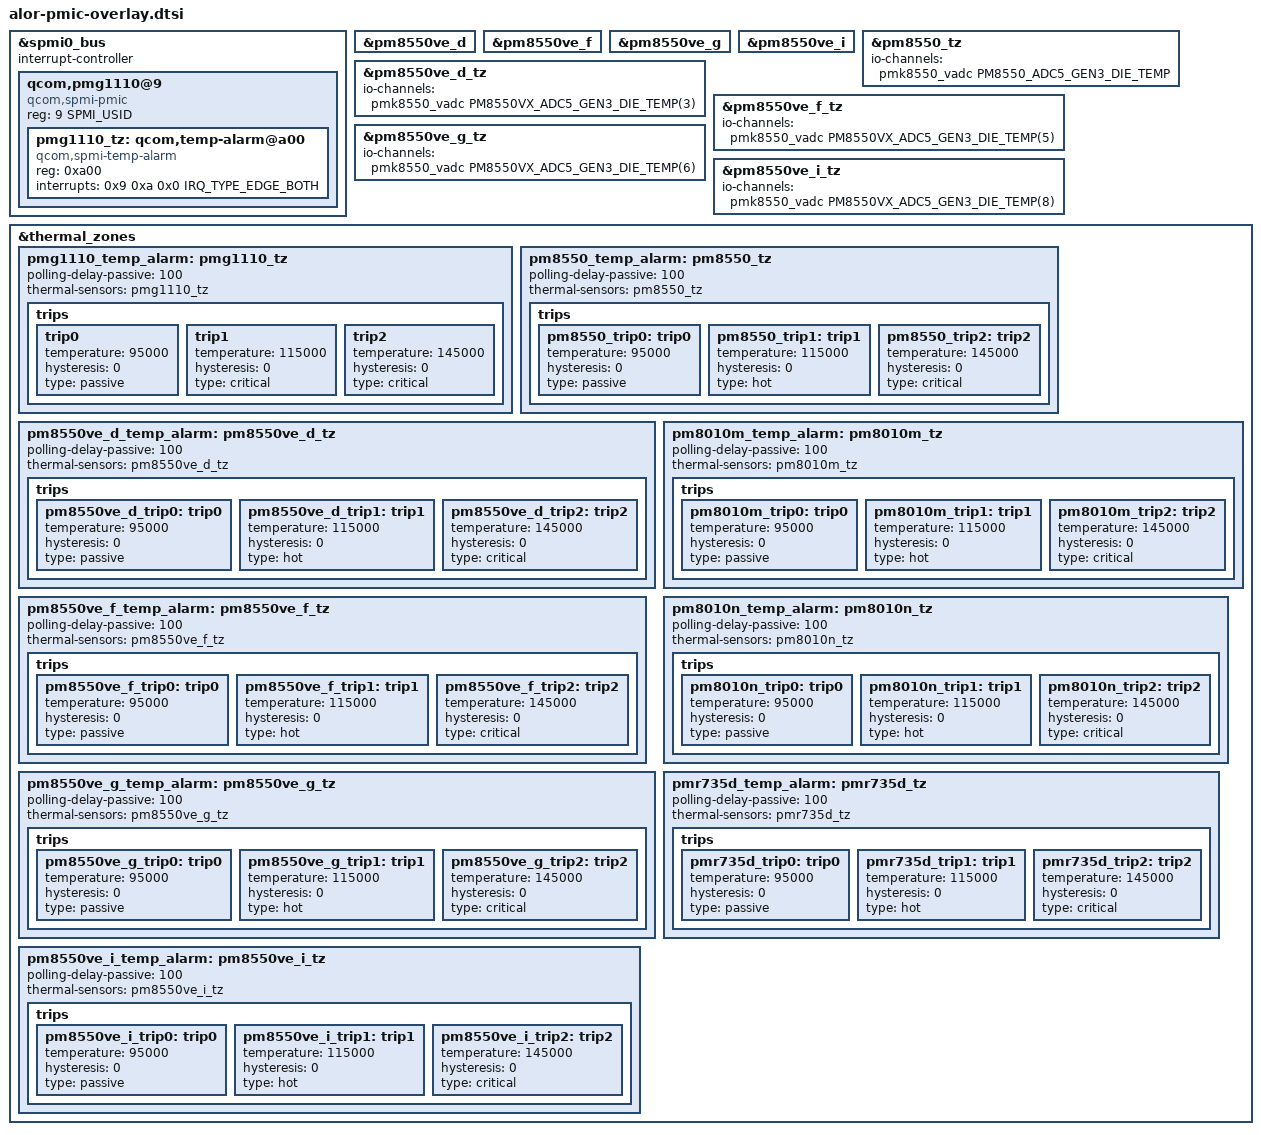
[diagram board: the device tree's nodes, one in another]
// SPDX-License-Identifier: BSD-3-Clause
/*
 * Copyright (c) 2025 Qualcomm Innovation Center, Inc. All rights reserved.
 */

#include <dt-bindings/gpio/gpio.h>

&spmi0_bus {
	#include "pmk8550.dtsi"
	#include "pm8550.dtsi"
	#include "pm8550ve.dtsi"
	#include "pmr735d.dtsi"
	#include "pm8010.dtsi"
};

&pm8550ve_d {
	status = "ok";
};

&pm8550ve_f {
	status = "ok";
};

&pm8550ve_g {
	status = "ok";
};

&pm8550ve_i {
	status = "ok";
};

&pm8550_tz {
	io-channels = <&pmk8550_vadc PM8550_ADC5_GEN3_DIE_TEMP>;
	io-channel-names = "thermal";
};

&pm8550ve_d_tz {
	io-channels = <&pmk8550_vadc PM8550VX_ADC5_GEN3_DIE_TEMP(3)>;
	io-channel-names = "thermal";
};

&pm8550ve_f_tz {
	io-channels = <&pmk8550_vadc PM8550VX_ADC5_GEN3_DIE_TEMP(5)>;
	io-channel-names = "thermal";
};

&pm8550ve_g_tz {
	io-channels = <&pmk8550_vadc PM8550VX_ADC5_GEN3_DIE_TEMP(6)>;
	io-channel-names = "thermal";
};

&pm8550ve_i_tz {
	io-channels = <&pmk8550_vadc PM8550VX_ADC5_GEN3_DIE_TEMP(8)>;
	io-channel-names = "thermal";
};

&spmi0_bus {
	#address-cells = <2>;
	#size-cells = <0>;
	interrupt-controller;
	#interrupt-cells = <4>;

	qcom,pmg1110@9 {
		compatible = "qcom,spmi-pmic";
		reg = <9 SPMI_USID>;
		#address-cells = <1>;
		#size-cells = <0>;

		pmg1110_tz: qcom,temp-alarm@a00 {
			compatible = "qcom,spmi-temp-alarm";
			reg = <0xa00>;
			interrupts = <0x9 0xa 0x0 IRQ_TYPE_EDGE_BOTH>;
			#thermal-sensor-cells = <0>;
		};
	};
};

&thermal_zones {
	pmg1110_temp_alarm: pmg1110_tz {
		polling-delay-passive = <100>;
		thermal-sensors = <&pmg1110_tz>;

		trips {
			trip0 {
				temperature = <95000>;
				hysteresis = <0>;
				type = "passive";
			};

			trip1 {
				temperature = <115000>;
				hysteresis = <0>;
				type = "critical";
			};

			trip2 {
				temperature = <145000>;
				hysteresis = <0>;
				type = "critical";
			};
		};
	};

	pm8550_temp_alarm: pm8550_tz {
		polling-delay-passive = <100>;
		thermal-sensors = <&pm8550_tz>;

		trips {
			pm8550_trip0: trip0 {
				temperature = <95000>;
				hysteresis = <0>;
				type = "passive";
			};

			pm8550_trip1: trip1 {
				temperature = <115000>;
				hysteresis = <0>;
				type = "hot";
			};

			pm8550_trip2: trip2 {
				temperature = <145000>;
				hysteresis = <0>;
				type = "critical";
			};
		};
	};

	pm8550ve_d_temp_alarm: pm8550ve_d_tz {
		polling-delay-passive = <100>;
		thermal-sensors = <&pm8550ve_d_tz>;

		trips {
			pm8550ve_d_trip0: trip0 {
				temperature = <95000>;
				hysteresis = <0>;
				type = "passive";
			};

			pm8550ve_d_trip1: trip1 {
				temperature = <115000>;
				hysteresis = <0>;
				type = "hot";
			};

			pm8550ve_d_trip2: trip2 {
				temperature = <145000>;
				hysteresis = <0>;
				type = "critical";
			};
		};
	};

	pm8550ve_f_temp_alarm: pm8550ve_f_tz {
		polling-delay-passive = <100>;
		thermal-sensors = <&pm8550ve_f_tz>;

		trips {
			pm8550ve_f_trip0: trip0 {
				temperature = <95000>;
				hysteresis = <0>;
				type = "passive";
			};

			pm8550ve_f_trip1: trip1 {
				temperature = <115000>;
				hysteresis = <0>;
				type = "hot";
			};

			pm8550ve_f_trip2: trip2 {
				temperature = <145000>;
				hysteresis = <0>;
				type = "critical";
			};
		};
	};

	pm8550ve_g_temp_alarm: pm8550ve_g_tz {
		polling-delay-passive = <100>;
		thermal-sensors = <&pm8550ve_g_tz>;

		trips {
			pm8550ve_g_trip0: trip0 {
				temperature = <95000>;
				hysteresis = <0>;
				type = "passive";
			};

			pm8550ve_g_trip1: trip1 {
				temperature = <115000>;
				hysteresis = <0>;
				type = "hot";
			};

			pm8550ve_g_trip2: trip2 {
				temperature = <145000>;
				hysteresis = <0>;
				type = "critical";
			};
		};
	};

	pm8550ve_i_temp_alarm: pm8550ve_i_tz {
		polling-delay-passive = <100>;
		thermal-sensors = <&pm8550ve_i_tz>;

		trips {
			pm8550ve_i_trip0: trip0 {
				temperature = <95000>;
				hysteresis = <0>;
				type = "passive";
			};

			pm8550ve_i_trip1: trip1 {
				temperature = <115000>;
				hysteresis = <0>;
				type = "hot";
			};

			pm8550ve_i_trip2: trip2 {
				temperature = <145000>;
				hysteresis = <0>;
				type = "critical";
			};
		};
	};

	pm8010m_temp_alarm: pm8010m_tz {
		polling-delay-passive = <100>;
		thermal-sensors = <&pm8010m_tz>;

		trips {
			pm8010m_trip0: trip0 {
				temperature = <95000>;
				hysteresis = <0>;
				type = "passive";
			};

			pm8010m_trip1: trip1 {
				temperature = <115000>;
				hysteresis = <0>;
				type = "hot";
			};

			pm8010m_trip2: trip2 {
				temperature = <145000>;
				hysteresis = <0>;
				type = "critical";
			};
		};
	};

	pm8010n_temp_alarm: pm8010n_tz {
		polling-delay-passive = <100>;
		thermal-sensors = <&pm8010n_tz>;

		trips {
			pm8010n_trip0: trip0 {
				temperature = <95000>;
				hysteresis = <0>;
				type = "passive";
			};

			pm8010n_trip1: trip1 {
				temperature = <115000>;
				hysteresis = <0>;
				type = "hot";
			};

			pm8010n_trip2: trip2 {
				temperature = <145000>;
				hysteresis = <0>;
				type = "critical";
			};
		};
	};

	pmr735d_temp_alarm: pmr735d_tz {
		polling-delay-passive = <100>;
		thermal-sensors = <&pmr735d_tz>;

		trips {
			pmr735d_trip0: trip0 {
				temperature = <95000>;
				hysteresis = <0>;
				type = "passive";
			};

			pmr735d_trip1: trip1 {
				temperature = <115000>;
				hysteresis = <0>;
				type = "hot";
			};

			pmr735d_trip2: trip2 {
				temperature = <145000>;
				hysteresis = <0>;
				type = "critical";
			};
		};
	};
};
